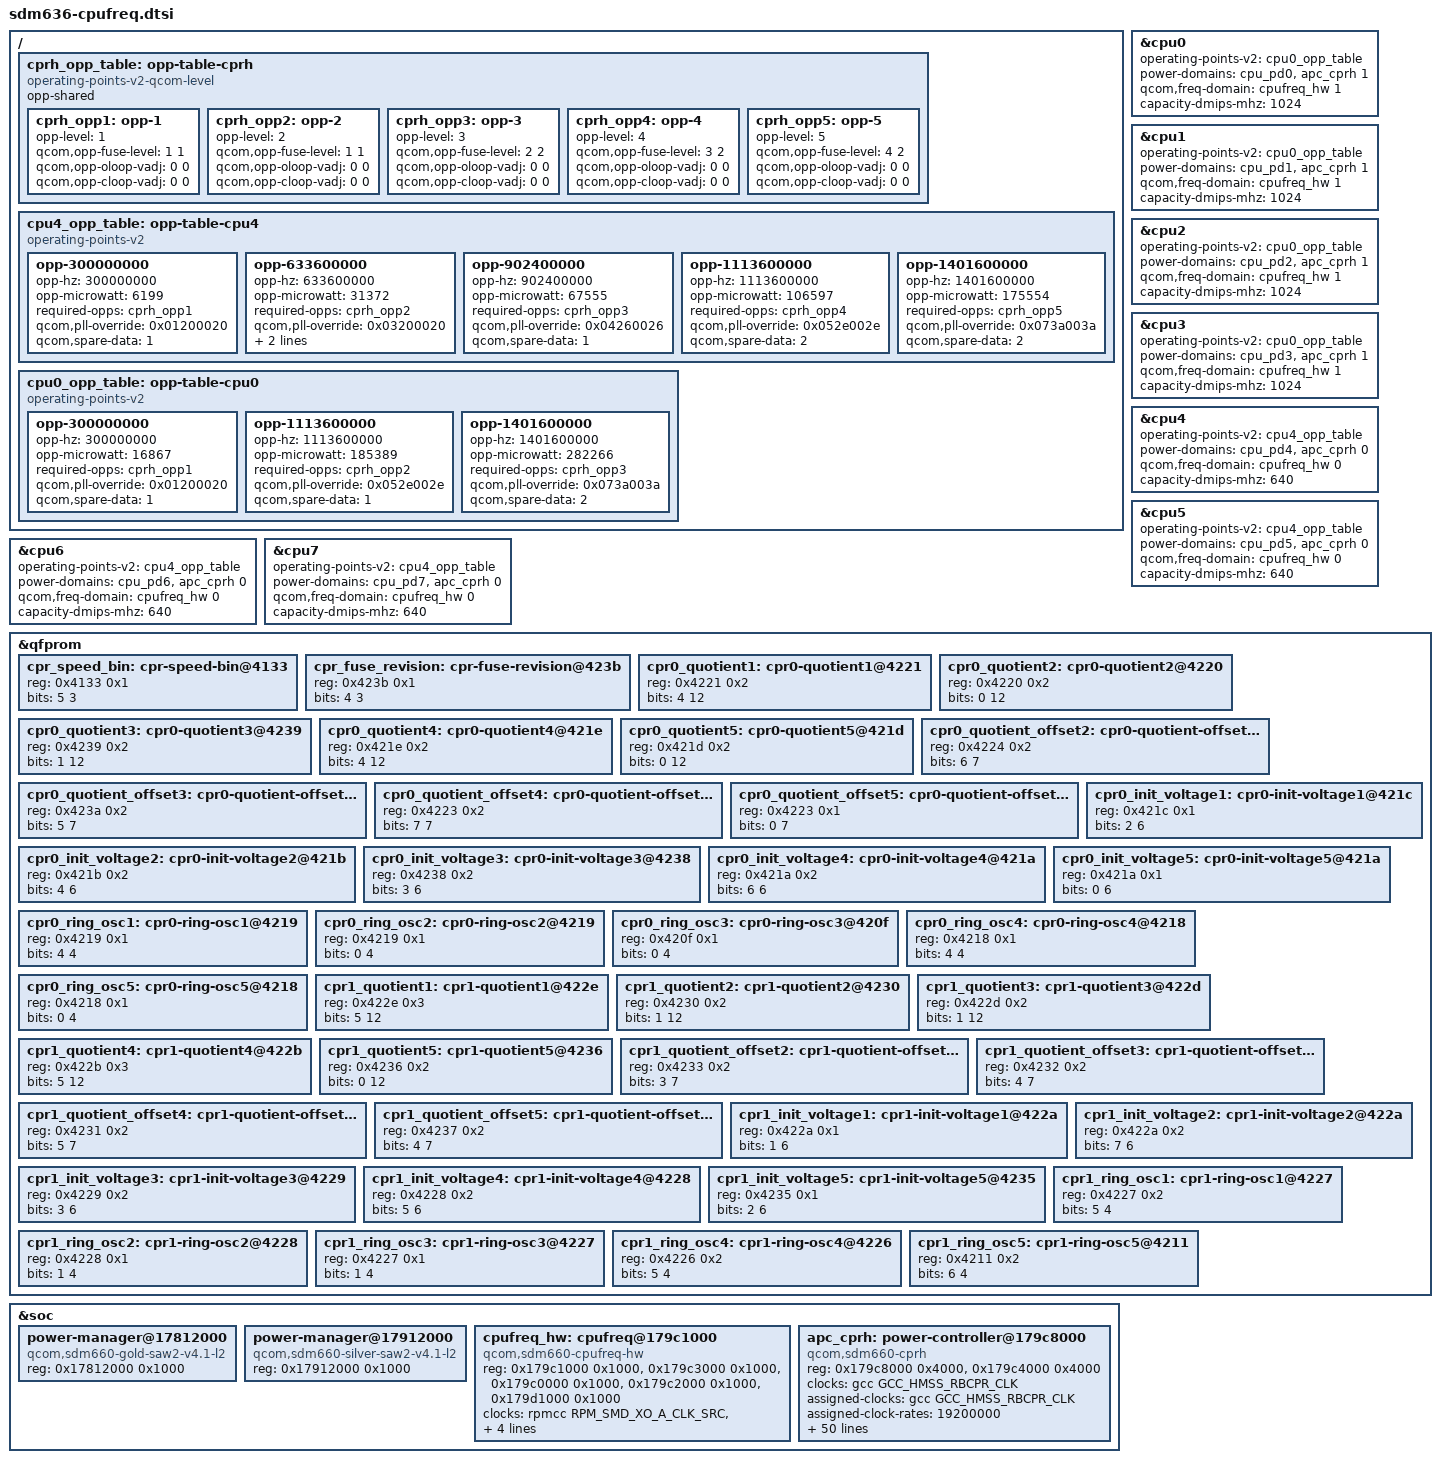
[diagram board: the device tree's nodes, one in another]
// SPDX-License-Identifier: GPL-2.0-only
/*
 * SDM636 (Onyx Boox Note Air 1) CPU DVFS: CPRh + OS-programmed OSM (cpufreq-hw)
 * + L2 SAW AVS, for the CPR3/OSM driver port on this branch.
 *
 * !! SPEED BIN 3 ONLY, CAPPED AT THE NOM FUSE CORNER !!
 *   Silver (cpu4-7, apc0, OSM domain 0): 300 / 633.6 / 902.4 / 1113.6 / 1401.6 MHz
 *   Gold   (cpu0-3, apc1, OSM domain 1): 300 / 1113.6 / 1401.6 MHz
 * Frequencies, PLL overrides, PLL dividers and mem-acc (spare) levels are the
 * downstream qcom,{pwrcl,perfcl}-speedbin3-v0 rows (sdm660.dtsi, Onyx stock DT);
 * voltages are NOT in here: they are computed by the CPRh driver from the fuses
 * (open-loop fused voltage + stock per-fuse-corner adjustment, clamped to the
 * stock ceiling) and printed at boot.
 *
 * The CPRh starts in open-loop only mode (qcom,cpr-open-loop-only): closed loop
 * disabled on every corner, floor = open-loop. Remove it only after the
 * open-loop run has been validated (see the report).
 *
 * The board DTS lowers gold's capacity-dmips-mhz for the no-cpufreq boot (gold left
 * at 600 MHz); with cpufreq both clusters reach 1401.6 MHz, so the end of this
 * file restores sdm660.dtsi's gold 1024 / silver 640.
 */

#include <dt-bindings/clock/qcom,gcc-sdm660.h>
#include <dt-bindings/clock/qcom,rpmcc.h>

/ {
	cprh_opp_table: opp-table-cprh {
		compatible = "operating-points-v2-qcom-level";
		opp-shared;

		/*
		 * qcom,opp-fuse-level = <silver gold>, fuse corners are 1-based:
		 *   silver: 1 LowSVS, 2 SVS, 3 SVS+, 4 NOM, 5 TURBO_L1
		 *   gold:   1 SVS, 2 SVS+, 3 NOM, 4 TURBO, 5 TURBO_L2
		 * Gold only uses levels 1-3: its entries in levels 4-5 are unused
		 * (the CPR driver stops at the first level with no gold CPU OPP).
		 * All the per-level adjustments are zero: the stock adjustments are
		 * per fuse corner and live in the driver.
		 */
		cprh_opp1: opp-1 {
			opp-level = <1>;
			qcom,opp-fuse-level = <1 1>;
			qcom,opp-oloop-vadj = <0 0>;
			qcom,opp-cloop-vadj = <0 0>;
		};

		cprh_opp2: opp-2 {
			opp-level = <2>;
			qcom,opp-fuse-level = <1 1>;
			qcom,opp-oloop-vadj = <0 0>;
			qcom,opp-cloop-vadj = <0 0>;
		};

		cprh_opp3: opp-3 {
			opp-level = <3>;
			qcom,opp-fuse-level = <2 2>;
			qcom,opp-oloop-vadj = <0 0>;
			qcom,opp-cloop-vadj = <0 0>;
		};

		cprh_opp4: opp-4 {
			opp-level = <4>;
			qcom,opp-fuse-level = <3 2>;
			qcom,opp-oloop-vadj = <0 0>;
			qcom,opp-cloop-vadj = <0 0>;
		};

		cprh_opp5: opp-5 {
			opp-level = <5>;
			qcom,opp-fuse-level = <4 2>;
			qcom,opp-oloop-vadj = <0 0>;
			qcom,opp-cloop-vadj = <0 0>;
		};
	};

	/* Silver: Power cluster, apc0, OSM domain 0 */
	cpu4_opp_table: opp-table-cpu4 {
		compatible = "operating-points-v2";
		/*
		 * No opp-shared: genpd's virtual device for the "perf" domain
		 * has the CPU's of_node, so a shared table is one table for both;
		 * the CPR attach fills it and genpd's required-dev setup on the
		 * CPU then hits a populated table (-EBUSY at first boot). The
		 * driver sets the cluster sharing itself (set_sharing_cpus).
		 * opp-microwatt: per CPU, EM v2 = log-space power-law fit (power
		 * measurements; v1's a f + b f^3 costed slow@300 at 2.8x fast@300
		 * per unit of work, EAS moved idle work to the fast cluster; v2:
		 * slow <= fast per unit of work at every speed): the energy model for EAS;
		 * the OPPs carry no voltage under CPRh. Escape: kernel.sched_energy_aware=0
		 */

		opp-300000000 {
			opp-hz = /bits/ 64 <300000000>;
			opp-microwatt = <6199>;
			required-opps = <&cprh_opp1>;
			qcom,pll-override = <0x01200020>;
			qcom,spare-data = <1>;
		};

		opp-633600000 {
			opp-hz = /bits/ 64 <633600000>;
			opp-microwatt = <31372>;
			required-opps = <&cprh_opp2>;
			qcom,pll-override = <0x03200020>;
			qcom,spare-data = <1>;
			qcom,pll-div = <1>;
		};

		opp-902400000 {
			opp-hz = /bits/ 64 <902400000>;
			opp-microwatt = <67555>;
			required-opps = <&cprh_opp3>;
			qcom,pll-override = <0x04260026>;
			qcom,spare-data = <1>;
		};

		opp-1113600000 {
			opp-hz = /bits/ 64 <1113600000>;
			opp-microwatt = <106597>;
			required-opps = <&cprh_opp4>;
			qcom,pll-override = <0x052e002e>;
			qcom,spare-data = <2>;
		};

		opp-1401600000 {
			opp-hz = /bits/ 64 <1401600000>;
			opp-microwatt = <175554>;
			required-opps = <&cprh_opp5>;
			qcom,pll-override = <0x073a003a>;
			qcom,spare-data = <2>;
		};
	};

	/* Gold: Performance cluster, apc1, OSM domain 1 */
	cpu0_opp_table: opp-table-cpu0 {
		compatible = "operating-points-v2";
		/*
		 * No opp-shared: genpd's virtual device for the "perf" domain
		 * has the CPU's of_node, so a shared table is one table for both;
		 * the CPR attach fills it and genpd's required-dev setup on the
		 * CPU then hits a populated table (-EBUSY at first boot). The
		 * driver sets the cluster sharing itself (set_sharing_cpus).
		 */

		opp-300000000 {
			opp-hz = /bits/ 64 <300000000>;
			opp-microwatt = <16867>;
			required-opps = <&cprh_opp1>;
			qcom,pll-override = <0x01200020>;
			qcom,spare-data = <1>;
		};

		opp-1113600000 {
			opp-hz = /bits/ 64 <1113600000>;
			opp-microwatt = <185389>;
			required-opps = <&cprh_opp2>;
			qcom,pll-override = <0x052e002e>;
			qcom,spare-data = <1>;
		};

		opp-1401600000 {
			opp-hz = /bits/ 64 <1401600000>;
			opp-microwatt = <282266>;
			required-opps = <&cprh_opp3>;
			qcom,pll-override = <0x073a003a>;
			qcom,spare-data = <2>;
		};
	};
};

/*
 * PSCI first: the idle-state lookup (of_get_cpu_state_node) reads index 0 of
 * power-domains; both drivers attach by name. Without cpu_pdN here this file
 * replaced the board DTS's PSCI domains and the CPUs had no idle states at all.
 */
&cpu0 {
	operating-points-v2 = <&cpu0_opp_table>;
	power-domains = <&cpu_pd0>, <&apc_cprh 1>;
	power-domain-names = "psci", "perf";
	qcom,freq-domain = <&cpufreq_hw 1>;
};

&cpu1 {
	operating-points-v2 = <&cpu0_opp_table>;
	power-domains = <&cpu_pd1>, <&apc_cprh 1>;
	power-domain-names = "psci", "perf";
	qcom,freq-domain = <&cpufreq_hw 1>;
};

&cpu2 {
	operating-points-v2 = <&cpu0_opp_table>;
	power-domains = <&cpu_pd2>, <&apc_cprh 1>;
	power-domain-names = "psci", "perf";
	qcom,freq-domain = <&cpufreq_hw 1>;
};

&cpu3 {
	operating-points-v2 = <&cpu0_opp_table>;
	power-domains = <&cpu_pd3>, <&apc_cprh 1>;
	power-domain-names = "psci", "perf";
	qcom,freq-domain = <&cpufreq_hw 1>;
};

&cpu4 {
	operating-points-v2 = <&cpu4_opp_table>;
	power-domains = <&cpu_pd4>, <&apc_cprh 0>;
	power-domain-names = "psci", "perf";
	qcom,freq-domain = <&cpufreq_hw 0>;
};

&cpu5 {
	operating-points-v2 = <&cpu4_opp_table>;
	power-domains = <&cpu_pd5>, <&apc_cprh 0>;
	power-domain-names = "psci", "perf";
	qcom,freq-domain = <&cpufreq_hw 0>;
};

&cpu6 {
	operating-points-v2 = <&cpu4_opp_table>;
	power-domains = <&cpu_pd6>, <&apc_cprh 0>;
	power-domain-names = "psci", "perf";
	qcom,freq-domain = <&cpufreq_hw 0>;
};

&cpu7 {
	operating-points-v2 = <&cpu4_opp_table>;
	power-domains = <&cpu_pd7>, <&apc_cprh 0>;
	power-domain-names = "psci", "perf";
	qcom,freq-domain = <&cpufreq_hw 0>;
};

&qfprom {
	/*
	 * CPR fuses: downstream "fuse_base" 0x784000 = qfprom + 0x4000, fuse row N
	 * at + 8 * N. Row/bit layout from cprh-kbss-regulator.c (sdm660_kbss_*).
	 * cpr0 = Silver (power cluster), cpr1 = Gold (performance cluster).
	 */
	cpr_speed_bin: cpr-speed-bin@4133 {
		reg = <0x4133 0x1>;
		bits = <5 3>;	/* row 38 bits 29-31 */
	};

	cpr_fuse_revision: cpr-fuse-revision@423b {
		reg = <0x423b 0x1>;
		bits = <4 3>;	/* row 71 bits 28-30 */
	};

	cpr0_quotient1: cpr0-quotient1@4221 {
		reg = <0x4221 0x2>;
		bits = <4 12>;	/* row 68 bits 12-23 */
	};

	cpr0_quotient2: cpr0-quotient2@4220 {
		reg = <0x4220 0x2>;
		bits = <0 12>;	/* row 68 bits 0-11 */
	};

	cpr0_quotient3: cpr0-quotient3@4239 {
		reg = <0x4239 0x2>;
		bits = <1 12>;	/* row 71 bits 9-20 */
	};

	cpr0_quotient4: cpr0-quotient4@421e {
		reg = <0x421e 0x2>;
		bits = <4 12>;	/* row 67 bits 52-63 */
	};

	cpr0_quotient5: cpr0-quotient5@421d {
		reg = <0x421d 0x2>;
		bits = <0 12>;	/* row 67 bits 40-51 */
	};

	cpr0_quotient_offset2: cpr0-quotient-offset2@4224 {
		reg = <0x4224 0x2>;
		bits = <6 7>;	/* row 68 bits 38-44 */
	};

	cpr0_quotient_offset3: cpr0-quotient-offset3@423a {
		reg = <0x423a 0x2>;
		bits = <5 7>;	/* row 71 bits 21-27 */
	};

	cpr0_quotient_offset4: cpr0-quotient-offset4@4223 {
		reg = <0x4223 0x2>;
		bits = <7 7>;	/* row 68 bits 31-37 */
	};

	cpr0_quotient_offset5: cpr0-quotient-offset5@4223 {
		reg = <0x4223 0x1>;
		bits = <0 7>;	/* row 68 bits 24-30 */
	};

	cpr0_init_voltage1: cpr0-init-voltage1@421c {
		reg = <0x421c 0x1>;
		bits = <2 6>;	/* row 67 bits 34-39 */
	};

	cpr0_init_voltage2: cpr0-init-voltage2@421b {
		reg = <0x421b 0x2>;
		bits = <4 6>;	/* row 67 bits 28-33 */
	};

	cpr0_init_voltage3: cpr0-init-voltage3@4238 {
		reg = <0x4238 0x2>;
		bits = <3 6>;	/* row 71 bits 3-8 */
	};

	cpr0_init_voltage4: cpr0-init-voltage4@421a {
		reg = <0x421a 0x2>;
		bits = <6 6>;	/* row 67 bits 22-27 */
	};

	cpr0_init_voltage5: cpr0-init-voltage5@421a {
		reg = <0x421a 0x1>;
		bits = <0 6>;	/* row 67 bits 16-21 */
	};

	cpr0_ring_osc1: cpr0-ring-osc1@4219 {
		reg = <0x4219 0x1>;
		bits = <4 4>;	/* row 67 bits 12-15 */
	};

	cpr0_ring_osc2: cpr0-ring-osc2@4219 {
		reg = <0x4219 0x1>;
		bits = <0 4>;	/* row 67 bits 8-11 */
	};

	cpr0_ring_osc3: cpr0-ring-osc3@420f {
		reg = <0x420f 0x1>;
		bits = <0 4>;	/* row 65 bits 56-59 */
	};

	cpr0_ring_osc4: cpr0-ring-osc4@4218 {
		reg = <0x4218 0x1>;
		bits = <4 4>;	/* row 67 bits 4-7 */
	};

	cpr0_ring_osc5: cpr0-ring-osc5@4218 {
		reg = <0x4218 0x1>;
		bits = <0 4>;	/* row 67 bits 0-3 */
	};

	cpr1_quotient1: cpr1-quotient1@422e {
		reg = <0x422e 0x3>;
		bits = <5 12>;	/* row 69 bits 53-70:0 */
	};

	cpr1_quotient2: cpr1-quotient2@4230 {
		reg = <0x4230 0x2>;
		bits = <1 12>;	/* row 70 bits 1-12 */
	};

	cpr1_quotient3: cpr1-quotient3@422d {
		reg = <0x422d 0x2>;
		bits = <1 12>;	/* row 69 bits 41-52 */
	};

	cpr1_quotient4: cpr1-quotient4@422b {
		reg = <0x422b 0x3>;
		bits = <5 12>;	/* row 69 bits 29-40 */
	};

	cpr1_quotient5: cpr1-quotient5@4236 {
		reg = <0x4236 0x2>;
		bits = <0 12>;	/* row 70 bits 48-59 */
	};

	cpr1_quotient_offset2: cpr1-quotient-offset2@4233 {
		reg = <0x4233 0x2>;
		bits = <3 7>;	/* row 70 bits 27-33 */
	};

	cpr1_quotient_offset3: cpr1-quotient-offset3@4232 {
		reg = <0x4232 0x2>;
		bits = <4 7>;	/* row 70 bits 20-26 */
	};

	cpr1_quotient_offset4: cpr1-quotient-offset4@4231 {
		reg = <0x4231 0x2>;
		bits = <5 7>;	/* row 70 bits 13-19 */
	};

	cpr1_quotient_offset5: cpr1-quotient-offset5@4237 {
		reg = <0x4237 0x2>;
		bits = <4 7>;	/* row 70 bits 60-71:2 */
	};

	cpr1_init_voltage1: cpr1-init-voltage1@422a {
		reg = <0x422a 0x1>;
		bits = <1 6>;	/* row 69 bits 17-22 */
	};

	cpr1_init_voltage2: cpr1-init-voltage2@422a {
		reg = <0x422a 0x2>;
		bits = <7 6>;	/* row 69 bits 23-28 */
	};

	cpr1_init_voltage3: cpr1-init-voltage3@4229 {
		reg = <0x4229 0x2>;
		bits = <3 6>;	/* row 69 bits 11-16 */
	};

	cpr1_init_voltage4: cpr1-init-voltage4@4228 {
		reg = <0x4228 0x2>;
		bits = <5 6>;	/* row 69 bits 5-10 */
	};

	cpr1_init_voltage5: cpr1-init-voltage5@4235 {
		reg = <0x4235 0x1>;
		bits = <2 6>;	/* row 70 bits 42-47 */
	};

	cpr1_ring_osc1: cpr1-ring-osc1@4227 {
		reg = <0x4227 0x2>;
		bits = <5 4>;	/* row 68 bits 61-69:0 */
	};

	cpr1_ring_osc2: cpr1-ring-osc2@4228 {
		reg = <0x4228 0x1>;
		bits = <1 4>;	/* row 69 bits 1-4 */
	};

	cpr1_ring_osc3: cpr1-ring-osc3@4227 {
		reg = <0x4227 0x1>;
		bits = <1 4>;	/* row 68 bits 57-60 */
	};

	cpr1_ring_osc4: cpr1-ring-osc4@4226 {
		reg = <0x4226 0x2>;
		bits = <5 4>;	/* row 68 bits 53-56 */
	};

	cpr1_ring_osc5: cpr1-ring-osc5@4211 {
		reg = <0x4211 0x2>;
		bits = <6 4>;	/* row 66 bits 14-17 */
	};
};

&soc {
	power-manager@17812000 {
		compatible = "qcom,sdm660-gold-saw2-v4.1-l2", "qcom,saw2";
		reg = <0x17812000 0x1000>;
	};

	power-manager@17912000 {
		compatible = "qcom,sdm660-silver-saw2-v4.1-l2", "qcom,saw2";
		reg = <0x17912000 0x1000>;
	};

	cpufreq_hw: cpufreq@179c1000 {
		compatible = "qcom,sdm660-cpufreq-hw";
		reg = <0x179c1000 0x1000>, <0x179c3000 0x1000>,
		      <0x179c0000 0x1000>, <0x179c2000 0x1000>,
		      <0x179d1000 0x1000>;
		reg-names = "freq-domain0", "freq-domain1",
			    "osm-domain0", "osm-domain1",
			    "apcs-common";

		clocks = <&rpmcc RPM_SMD_XO_A_CLK_SRC>, <&gcc HMSS_GPLL0_CLK_SRC>;
		clock-names = "xo", "alternate";

		/* LUT[0] (300 MHz) is sourced from this clock: it must be 300 MHz */
		assigned-clocks = <&gcc HMSS_GPLL0_CLK_SRC>;
		assigned-clock-rates = <300000000>;
		/*
		 * The OSM timers count a 200 MHz clock (APCS_COMMON_LMH RCG,
		 * source hmss_gpll0). The boot chain leaves it at div 3 from a
		 * 600 MHz hmss_gpll0; at 300 MHz (above) that is 100 MHz (seen at
		 * first boot: cfg=0x105): have the driver set div 1.5 at probe,
		 * before any OSM domain is enabled.
		 */
		qcom,osm-clk-program;

		#freq-domain-cells = <1>;
		#clock-cells = <1>;
	};

	apc_cprh: power-controller@179c8000 {
		compatible = "qcom,sdm660-cprh", "qcom,cprh";
		/* controller 0 = apc0 (Silver), controller 1 = apc1 (Gold) */
		reg = <0x179c8000 0x4000>, <0x179c4000 0x4000>;

		clocks = <&gcc GCC_HMSS_RBCPR_CLK>;
		assigned-clocks = <&gcc GCC_HMSS_RBCPR_CLK>;
		assigned-clock-rates = <19200000>;

		operating-points-v2 = <&cprh_opp_table>;
		#power-domain-cells = <1>;

		/* Bring-up safety: see the report before removing either */
		qcom,cpr-open-loop-only;
		qcom,cpr-expected-speed-bin = <3>;

		nvmem-cells = <&cpr_speed_bin>,
			      <&cpr_fuse_revision>,
			      <&cpr0_quotient1>,
			      <&cpr0_quotient2>,
			      <&cpr0_quotient3>,
			      <&cpr0_quotient4>,
			      <&cpr0_quotient5>,
			      <&cpr0_quotient_offset2>,
			      <&cpr0_quotient_offset3>,
			      <&cpr0_quotient_offset4>,
			      <&cpr0_quotient_offset5>,
			      <&cpr0_init_voltage1>,
			      <&cpr0_init_voltage2>,
			      <&cpr0_init_voltage3>,
			      <&cpr0_init_voltage4>,
			      <&cpr0_init_voltage5>,
			      <&cpr0_ring_osc1>,
			      <&cpr0_ring_osc2>,
			      <&cpr0_ring_osc3>,
			      <&cpr0_ring_osc4>,
			      <&cpr0_ring_osc5>,
			      <&cpr1_quotient1>,
			      <&cpr1_quotient2>,
			      <&cpr1_quotient3>,
			      <&cpr1_quotient4>,
			      <&cpr1_quotient5>,
			      <&cpr1_quotient_offset2>,
			      <&cpr1_quotient_offset3>,
			      <&cpr1_quotient_offset4>,
			      <&cpr1_quotient_offset5>,
			      <&cpr1_init_voltage1>,
			      <&cpr1_init_voltage2>,
			      <&cpr1_init_voltage3>,
			      <&cpr1_init_voltage4>,
			      <&cpr1_init_voltage5>,
			      <&cpr1_ring_osc1>,
			      <&cpr1_ring_osc2>,
			      <&cpr1_ring_osc3>,
			      <&cpr1_ring_osc4>,
			      <&cpr1_ring_osc5>;
		nvmem-cell-names = "cpr_speed_bin",
				   "cpr_fuse_revision",
				   "cpr0_quotient1",
				   "cpr0_quotient2",
				   "cpr0_quotient3",
				   "cpr0_quotient4",
				   "cpr0_quotient5",
				   "cpr0_quotient_offset2",
				   "cpr0_quotient_offset3",
				   "cpr0_quotient_offset4",
				   "cpr0_quotient_offset5",
				   "cpr0_init_voltage1",
				   "cpr0_init_voltage2",
				   "cpr0_init_voltage3",
				   "cpr0_init_voltage4",
				   "cpr0_init_voltage5",
				   "cpr0_ring_osc1",
				   "cpr0_ring_osc2",
				   "cpr0_ring_osc3",
				   "cpr0_ring_osc4",
				   "cpr0_ring_osc5",
				   "cpr1_quotient1",
				   "cpr1_quotient2",
				   "cpr1_quotient3",
				   "cpr1_quotient4",
				   "cpr1_quotient5",
				   "cpr1_quotient_offset2",
				   "cpr1_quotient_offset3",
				   "cpr1_quotient_offset4",
				   "cpr1_quotient_offset5",
				   "cpr1_init_voltage1",
				   "cpr1_init_voltage2",
				   "cpr1_init_voltage3",
				   "cpr1_init_voltage4",
				   "cpr1_init_voltage5",
				   "cpr1_ring_osc1",
				   "cpr1_ring_osc2",
				   "cpr1_ring_osc3",
				   "cpr1_ring_osc4",
				   "cpr1_ring_osc5";
	};
};

/*
 * sdm660.dtsi's per-clock capacities (gold ~1.6x silver; measured
 * 1.4-2x with gold at 600 and silver at 1382.4 MHz). Both clusters top out
 * at 1401.6 MHz here, so gold is the faster one again: undo the board DTS
 * overrides, which are only right without cpufreq.
 */
&cpu0 { capacity-dmips-mhz = <1024>; };
&cpu1 { capacity-dmips-mhz = <1024>; };
&cpu2 { capacity-dmips-mhz = <1024>; };
&cpu3 { capacity-dmips-mhz = <1024>; };
&cpu4 { capacity-dmips-mhz = <640>; };
&cpu5 { capacity-dmips-mhz = <640>; };
&cpu6 { capacity-dmips-mhz = <640>; };
&cpu7 { capacity-dmips-mhz = <640>; };
